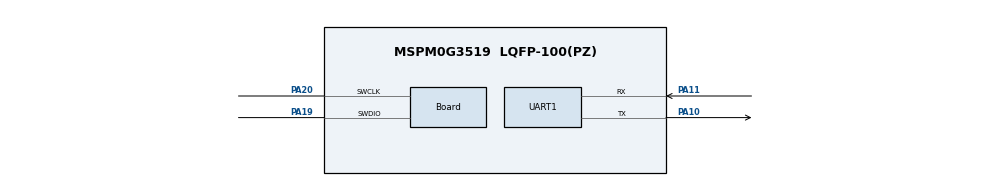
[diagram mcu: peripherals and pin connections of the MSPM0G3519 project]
/**
 * Port of MaJerle usart_rx_idle_line_irq_ringbuff_tx_G0 to LP-MSPM0G3519.
 */
//@cliArgs --device "MSPM0G351X" --package "LQFP-100(PZ)" --part "Default"
//@v2CliArgs --device "MSPM0G3519" --package "LQFP-100(PZ)"
// @cliArgs --board /ti/boards/LP_MSPM0G3519 --rtos nortos

const SYSCTL = scripting.addModule("/ti/driverlib/SYSCTL");
const UART   = scripting.addModule("/ti/driverlib/UART", {}, false);
const UART1  = UART.addInstance();

const Board                       = scripting.addModule("/ti/driverlib/Board", {}, false);
Board.peripheral.$assign          = "DEBUGSS";
Board.peripheral.swclkPin.$assign = "PA20";
Board.peripheral.swdioPin.$assign = "PA19";

SYSCTL.forceDefaultClkConfig = true;
SYSCTL.clockTreeEn           = true;

/* Back-channel UART (XDS110): UART0, PA10 TX / PA11 RX. Baud is re-applied from USART_BAUD in main.c */
UART1.$name                             = "UART_0";
UART1.targetBaudRate                    = 115200;
UART1.enableFIFO                        = true;
UART1.rxFifoThreshold                   = "DL_UART_RX_FIFO_LEVEL_ONE_ENTRY";
UART1.txFifoThreshold                   = "DL_UART_TX_FIFO_LEVEL_ONE_ENTRY";
UART1.enabledDMARXTriggers              = "DL_UART_DMA_INTERRUPT_RX";
UART1.enabledDMATXTriggers              = "DL_UART_DMA_INTERRUPT_TX";
UART1.peripheral.$assign                = "UART0";
UART1.peripheral.rxPin.$assign          = "PA11";
UART1.peripheral.txPin.$assign          = "PA10";
UART1.DMA_CHANNEL_RX.$name              = "DMA_CH_RX";
UART1.DMA_CHANNEL_RX.addressMode        = "f2b";
UART1.DMA_CHANNEL_RX.transferMode       = "FULL_CH_REPEAT_SINGLE";
UART1.DMA_CHANNEL_RX.dstLength          = "BYTE";
UART1.DMA_CHANNEL_RX.srcLength          = "BYTE";
UART1.DMA_CHANNEL_RX.peripheral.$assign = "DMA_CH0";
UART1.DMA_CHANNEL_TX.$name              = "DMA_CH_TX";
UART1.DMA_CHANNEL_TX.addressMode        = "b2f";
UART1.DMA_CHANNEL_TX.dstLength          = "BYTE";
UART1.DMA_CHANNEL_TX.srcLength          = "BYTE";
UART1.DMA_CHANNEL_TX.peripheral.$assign = "DMA_CH1";

const ProjectConfig              = scripting.addModule("/ti/project_config/ProjectConfig", {}, false);
ProjectConfig.migrationCondition = true;
